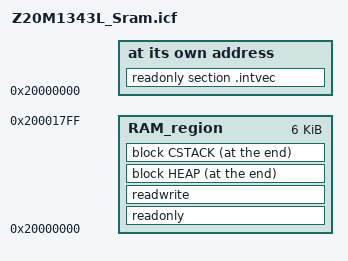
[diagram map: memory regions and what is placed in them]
/*###ICF### Section handled by ICF editor, don't touch! ****/
/*-Editor annotation file-*/
/* IcfEditorFile="$TOOLKIT_DIR$\config\ide\IcfEditor\cortex_v1_0.xml" */
/*-Specials-*/
define symbol __ICFEDIT_intvec_start__           = 0x20000000;
/*-Memory Regions-*/
define symbol __ICFEDIT_region_RAM_start__       = 0x20000000; 
define symbol __ICFEDIT_region_RAM_end__         = 0x200017FF;   /* 6KB */

define symbol __ICFEDIT_size_cstack__            = 0x00000200;   /* 512B */
define symbol __ICFEDIT_size_heap__              = 0x00000100;   /* 256B */

/**** End of ICF editor section. ###ICF###*/

define exported symbol __RAM_START             = __ICFEDIT_region_RAM_start__;
define exported symbol __RAM_END               = __ICFEDIT_region_RAM_end__;

/* memory range */
define memory mem with size = 4G;

define region RAM_region        = mem:[from __ICFEDIT_region_RAM_start__ to __ICFEDIT_region_RAM_end__];

/* definition of RAM blocks */
define block CSTACK    with size = __ICFEDIT_size_cstack__, alignment = 8 { };
define block HEAP      with size = __ICFEDIT_size_heap__, alignment = 8  { };

initialize by copy { readwrite };
do not initialize  { section .noinit };

place at address mem:__ICFEDIT_intvec_start__ { readonly section .intvec };

place in RAM_region  { readonly,readwrite };

place at end of RAM_region { block HEAP, block CSTACK };
